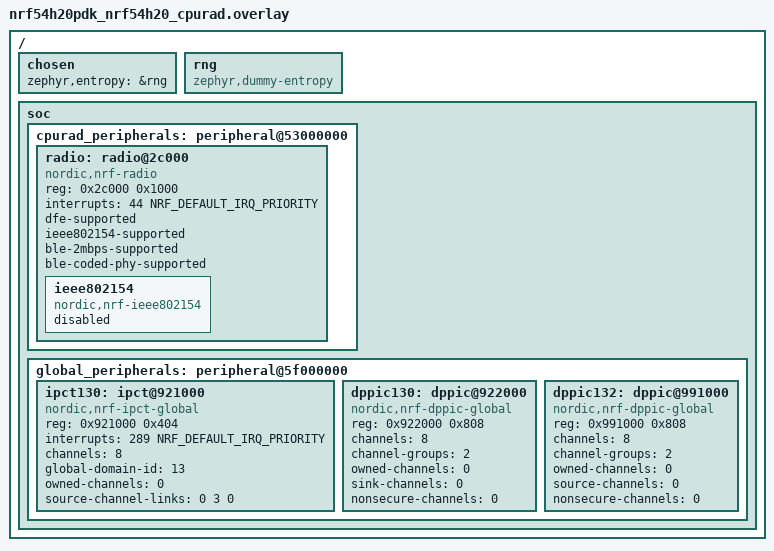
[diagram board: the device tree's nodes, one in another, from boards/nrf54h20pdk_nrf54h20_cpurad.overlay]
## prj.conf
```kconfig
#
# Copyright (c) 2018 Nordic Semiconductor
#
# SPDX-License-Identifier: LicenseRef-Nordic-5-Clause
#
CONFIG_NCS_SAMPLES_DEFAULTS=y

CONFIG_SHELL=y

CONFIG_BT_DEVICE_NAME="Nordic_Throughput"
CONFIG_BT=y
CONFIG_LOG=n
CONFIG_BT_DEBUG_LOG=n
CONFIG_BT_SMP=y
CONFIG_BT_PERIPHERAL=y
CONFIG_BT_CENTRAL=y
CONFIG_BT_MAX_CONN=2
CONFIG_BT_BONDABLE=n

CONFIG_BT_SCAN=y
CONFIG_BT_SCAN_FILTER_ENABLE=y
CONFIG_BT_SCAN_UUID_CNT=1

CONFIG_BT_GATT_CLIENT=y
CONFIG_BT_THROUGHPUT=y

CONFIG_BT_GATT_DM=y
CONFIG_HEAP_MEM_POOL_SIZE=2048

CONFIG_BT_USER_DATA_LEN_UPDATE=y
CONFIG_BT_USER_PHY_UPDATE=y
CONFIG_BT_GAP_AUTO_UPDATE_CONN_PARAMS=n

CONFIG_BT_BUF_ACL_RX_SIZE=502
CONFIG_BT_ATT_PREPARE_COUNT=2
CONFIG_BT_L2CAP_TX_BUF_COUNT=10
CONFIG_BT_L2CAP_TX_MTU=498
CONFIG_BT_L2CAP_DYNAMIC_CHANNEL=y
CONFIG_BT_CONN_TX_MAX=10
CONFIG_BT_BUF_ACL_TX_COUNT=10
CONFIG_BT_BUF_ACL_TX_SIZE=502

CONFIG_BT_CTLR_DATA_LENGTH_MAX=251
CONFIG_BT_CTLR_PHY_2M=y
CONFIG_BT_CTLR_PHY_CODED=y
CONFIG_BT_CTLR_SDC_MAX_CONN_EVENT_LEN_DEFAULT=4000000

CONFIG_DK_LIBRARY=n
CONFIG_DK_LIBRARY_DYNAMIC_BUTTON_HANDLERS=n
```

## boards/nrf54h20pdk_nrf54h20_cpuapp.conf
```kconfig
CONFIG_ENTROPY_DEVICE_RANDOM_GENERATOR=n
CONFIG_HARDWARE_DEVICE_CS_GENERATOR=n
CONFIG_CTR_DRBG_CSPRNG_GENERATOR=n

CONFIG_TEST_RANDOM_GENERATOR=y
CONFIG_TIMER_RANDOM_GENERATOR=y
CONFIG_ENTROPY_DUMMY=y

CONFIG_BT_CTLR=n
CONFIG_BT_HCI_IPC=y
```

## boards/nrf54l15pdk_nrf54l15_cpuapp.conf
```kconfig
# CONFIG_ENTROPY_DEVICE_RANDOM_GENERATOR=n
# CONFIG_HARDWARE_DEVICE_CS_GENERATOR=n
# CONFIG_CTR_DRBG_CSPRNG_GENERATOR=n

# CONFIG_TEST_RANDOM_GENERATOR=y
# CONFIG_TIMER_RANDOM_GENERATOR=y
# CONFIG_ENTROPY_DUMMY=y

CONFIG_BT_CTLR=y
# CONFIG_TMP_RNG=y

# Enable nordic security backend and PSA APIs
CONFIG_NRF_SECURITY=y
CONFIG_MBEDTLS_PSA_CRYPTO_C=y

CONFIG_MBEDTLS_ENABLE_HEAP=y
CONFIG_MBEDTLS_HEAP_SIZE=8192

CONFIG_PSA_WANT_GENERATE_RANDOM=y
```

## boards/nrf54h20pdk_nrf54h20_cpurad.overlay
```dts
/{
    chosen {
        zephyr,entropy = &rng;
    };

    rng: rng {
        compatible = "zephyr,dummy-entropy";
        status = "okay";
    };

    soc {
        cpurad_peripherals: peripheral@53000000 {
            radio: radio@2c000 {
                compatible = "nordic,nrf-radio";
                reg = <0x2c000 0x1000>;
                interrupts = <44 NRF_DEFAULT_IRQ_PRIORITY>;
                status = "okay";
                dfe-supported;
                ieee802154-supported;
                ble-2mbps-supported;
                ble-coded-phy-supported;

                ieee802154: ieee802154 {
                    compatible = "nordic,nrf-ieee802154";
                    status = "disabled";
                };
            };
        };

        global_peripherals: peripheral@5f000000 {
            /* MPSL requires one global DPPI channel which is routed to the radiocore */
            ipct130: ipct@921000 {
                compatible = "nordic,nrf-ipct-global";
                reg = <0x921000 0x404>;
                interrupts = <289 NRF_DEFAULT_IRQ_PRIORITY>;
                channels = <8>;
                global-domain-id = <13>;
                owned-channels = <0>;
                source-channel-links = <0 3 0>;
                status = "okay";
            };

            dppic130: dppic@922000 {
                compatible = "nordic,nrf-dppic-global";
                reg = <0x922000 0x808>;
                channels = <8>;
                channel-groups = <2>;
                owned-channels = <0>;
                sink-channels = <0>;
                nonsecure-channels = <0>;
                status = "okay";
            };

            dppic132: dppic@991000 {
                compatible = "nordic,nrf-dppic-global";
                reg = <0x991000 0x808>;
                channels = <8>;
                channel-groups = <2>;
                owned-channels = <0>;
                source-channels = <0>;
                nonsecure-channels = <0>;
                status = "okay";
            };
        };
    };
};
```

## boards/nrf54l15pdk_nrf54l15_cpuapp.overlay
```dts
/{
    chosen {
        zephyr,entropy = &psa_rng;
        // zephyr,entropy = &rng;
    };

    // rng: rng {
        //     compatible = "zephyr,dummy-entropy";
        //     status = "okay";
    // };

    psa_rng: psa-rng {
        compatible = "zephyr,psa-crypto-rng";
        status = "okay";
    };

};
```

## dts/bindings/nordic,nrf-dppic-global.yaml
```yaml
#
# Copyright (c) 2022 Nordic Semiconductor ASA
#
# SPDX-License-Identifier: LicenseRef-Nordic-4-Clause
#

description: |
  Nordic Global DPPIC
  (Distributed Programmable Peripheral Interconnect Controller)

  Updated DPPIC binding set for Nordic products that have global DPPIC instances
  with inter-bridge functionality. These instances also have split-ownership
  of its channels and channel groups.

compatible: "nordic,nrf-dppic-global"

include:
  - "nordic,nrf-dppic.yaml"
  - "nordic,nrf-dppic-links.yaml"
  - "nordic,nrf-fixed-channel-links.yaml"
  - "nordic,split-channels.yaml"
  - "nordic,split-channel-groups.yaml"

properties:
    channels:
      required: true
      type: int
      description: Number of DPPI channels implemented by the DPPIC.

    channel-groups:
      type: int
      description: |
        Number of DPPI channel groups implemented by the DPPIC.
        If not present, the DPPIC does not implement channel groups.
```

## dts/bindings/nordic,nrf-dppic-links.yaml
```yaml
#
# Copyright (c) 2022 Nordic Semiconductor ASA
#
# SPDX-License-Identifier: LicenseRef-Nordic-4-Clause
#

description: Nordic DPPIC Channel Linking

properties:
    source-channels:
      type: array
      description: |
        Channels that are linked to channels of DPPIC instances on separate
        bridges as publishing sources.

    sink-channels:
      type: array
      description: |
        Channels that are linked to channels of DPPIC instances on separate
        bridges as subscribing sinks.
```

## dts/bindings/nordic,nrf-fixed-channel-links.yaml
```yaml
#
# Copyright (c) 2022 Nordic Semiconductor ASA
#
# SPDX-License-Identifier: LicenseRef-Nordic-4-Clause
#

description: |
  Nordic Fixed Channel Links

  Contains common bindings that describe fixed (hardwired) channel connections
  from a peripheral node to another peripheral node.

properties:
    fixed-channel-links:
      type: phandle-array
      description: |
        A list of ranges of linked channels between this peripheral node and
        another peripheral node. The prop is encoded as
        <&phandle src-ch-start dst-ch-start count>, where:
        - phandle is the phandle of the linked peripheral node
        - src-ch-start is the starting index of the channel range in this node
        - dst-ch-start is the starting index of the channel range in the linked
          node
        - count is the number of consecutive linked channels starting at the
          start indices

fixed-channel-link-cells:
  - src-ch-start
  - dst-ch-start
  - count
```

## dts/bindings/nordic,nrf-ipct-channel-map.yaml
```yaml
#
# Copyright (c) 2022 Nordic Semiconductor ASA
#
# SPDX-License-Identifier: LicenseRef-Nordic-4-Clause
#

description: Nordic IPCT Channel Map

properties:
    source-channel-links:
      type: array
      description: |
        Mapping of IPCT channels that are mapped between two IPCT instances on
        separate domains, in which a channel on this IPCT node is considered
        the source. This array is then comprised of a 3-integer-wide "unit"
        that defines one connection of the mapping. The format of this unit
        is <source_channel sink_domain_id sink_channel>. Units are sequential
        in the array, therefore requiring the length of this property to be
        a factor of 3.

        For example, if channel 2 is to be mapped to Secure Domain (ID: 1) IPCT
        channel 4, then the array "unit" would be <2 1 4>.

    sink-channel-links:
      type: array
      description: |
        Mapping of IPCT channels that are mapped between two IPCT instances on
        separate domains, in which a channel on this IPCT node is considered
        the sink. This array is then comprised of a 3-integer-wide "unit"
        that defines one connection of the mapping. The format of this unit
        is <sink_channel source_domain_id source_channel>. Units are sequential
        in the array, therefore requiring the length of this property to be
        a factor of 3.

        For example, if channel 2 is to be mapped to Secure Domain (ID: 1) IPCT
        channel 4, then the array "unit" would be <2 1 4>.
```

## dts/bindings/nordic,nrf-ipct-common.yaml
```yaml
#
# Copyright (c) 2022 Nordic Semiconductor ASA
#
# SPDX-License-Identifier: LicenseRef-Nordic-4-Clause
#

description: Nordic IPCT (Interprocessor Communication Transceiver)

include: ["base.yaml", "nordic,nrf-ipct-channel-map.yaml"]

properties:
    reg:
      required: true

    channels:
      type: int
      required: true
      description: Number of channels implemented by the IPCT instance.
```

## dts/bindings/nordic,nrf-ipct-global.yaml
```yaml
#
# Copyright (c) 2022 Nordic Semiconductor ASA
#
# SPDX-License-Identifier: LicenseRef-Nordic-4-Clause
#

description: Nordic Global IPCT (Interprocessor Communication Transceiver)

compatible: "nordic,nrf-ipct-global"

include: ["nordic,nrf-ipct-common.yaml", "nordic,split-channels.yaml"]

properties:
    global-domain-id:
      required: true
      type: int
      description: |
        Global IPCT instances reside on specific buses within the Global Domain,
        such as fast and slow, which have different IDs that do not match the
        standard Global Domain ID presented in their address.
```

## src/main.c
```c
/*
 * Copyright (c) 2018 Nordic Semiconductor ASA
 *
 * SPDX-License-Identifier: LicenseRef-Nordic-5-Clause
 */

#include <zephyr/kernel.h>
#include <zephyr/console/console.h>
#include <zephyr/sys/printk.h>
#include <string.h>
#include <stdlib.h>
#include <zephyr/types.h>

#include <zephyr/bluetooth/bluetooth.h>
#include <zephyr/bluetooth/crypto.h>
#include <zephyr/bluetooth/conn.h>
#include <zephyr/bluetooth/gatt.h>
#include <zephyr/bluetooth/hci.h>
#include <zephyr/bluetooth/uuid.h>
#include <bluetooth/services/throughput.h>
#include <bluetooth/scan.h>
#include <bluetooth/gatt_dm.h>

#include <zephyr/shell/shell_uart.h>

// #include <dk_buttons_and_leds.h>

#ifdef shell_error
#undef shell_error
#endif

#define shell_error(sh, ...) printk(__VA_ARGS__)

#include "main.h"

#define DEVICE_NAME	CONFIG_BT_DEVICE_NAME
#define DEVICE_NAME_LEN (sizeof(DEVICE_NAME) - 1)
#define INTERVAL_MIN	0x6	/* 6 units, 7.5 ms, only used to setup connection */
#define INTERVAL_MAX	0x6	/* 6 units, 7.5 ms, only used to setup connection */

#define THROUGHPUT_CONFIG_TIMEOUT K_SECONDS(20)

static K_SEM_DEFINE(throughput_sem, 0, 1);

static volatile bool data_length_req;
static volatile bool test_ready;
static struct bt_conn *default_conn;
static struct bt_throughput throughput;
static struct bt_uuid *uuid128 = BT_UUID_THROUGHPUT;
static struct bt_gatt_exchange_params exchange_params;
static struct bt_le_conn_param *conn_param =
	BT_LE_CONN_PARAM(INTERVAL_MIN, INTERVAL_MAX, 0, 400);

static const struct bt_data ad[] = {
	BT_DATA_BYTES(BT_DATA_FLAGS, (BT_LE_AD_GENERAL | BT_LE_AD_NO_BREDR)),
	BT_DATA_BYTES(BT_DATA_UUID128_ALL,
		0xBB, 0x4A, 0xFF, 0x4F, 0xAD, 0x03, 0x41, 0x5D,
		0xA9, 0x6C, 0x9D, 0x6C, 0xDD, 0xDA, 0x83, 0x04),
};

static const struct bt_data sd[] = {
	BT_DATA(BT_DATA_NAME_COMPLETE, DEVICE_NAME, DEVICE_NAME_LEN),
};

static const char img[] =
#include "img.file"
;

// static void button_handler_cb(uint32_t button_state, uint32_t has_changed);

static const char *phy2str(uint8_t phy)
{
	switch (phy) {
	case 0: return "No packets";
	case BT_GAP_LE_PHY_1M: return "LE 1M";
	case BT_GAP_LE_PHY_2M: return "LE 2M";
	case BT_GAP_LE_PHY_CODED: return "LE Coded";
	default: return "Unknown";
	}
}

static void instruction_print(void)
{
	printk("\nType 'config' to change the configuration parameters.\n");
	printk("You can use the Tab key to autocomplete your input.\n");
	printk("Type 'run' when you are ready to run the test.\n");
}

void scan_filter_match(struct bt_scan_device_info *device_info,
		       struct bt_scan_filter_match *filter_match,
		       bool connectable)
{
	char addr[BT_ADDR_LE_STR_LEN];

	bt_addr_le_to_str(device_info->recv_info->addr, addr, sizeof(addr));

	printk("Filters matched. Address: %s connectable: %d\n",
		addr, connectable);
}

void scan_filter_no_match(struct bt_scan_device_info *device_info,
			  bool connectable)
{
	char addr[BT_ADDR_LE_STR_LEN];

	bt_addr_le_to_str(device_info->recv_info->addr, addr, sizeof(addr));

	printk("Filter not match. Address: %s connectable: %d\n",
				addr, connectable);
}

void scan_connecting_error(struct bt_scan_device_info *device_info)
{
	printk("Connecting failed\n");
}

BT_SCAN_CB_INIT(scan_cb, scan_filter_match, scan_filter_no_match,
		scan_connecting_error, NULL);

static void exchange_func(struct bt_conn *conn, uint8_t att_err,
			  struct bt_gatt_exchange_params *params)
{
	struct bt_conn_info info = {0};
	int err;

	printk("MTU exchange %s\n", att_err == 0 ? "successful" : "failed");

	err = bt_conn_get_info(conn, &info);
	if (err) {
		printk("Failed to get connection info %d\n", err);
		return;
	}

	if (info.role == BT_CONN_ROLE_CENTRAL) {
		instruction_print();
		test_ready = true;
	}
}

static void discovery_complete(struct bt_gatt_dm *dm,
			       void *context)
{
	int err;
	struct bt_throughput *throughput = context;

	printk("Service discovery completed\n");

	bt_gatt_dm_data_print(dm);
	bt_throughput_handles_assign(dm, throughput);
	bt_gatt_dm_data_release(dm);

	exchange_params.func = exchange_func;

	err = bt_gatt_exchange_mtu(default_conn, &exchange_params);
	if (err) {
		printk("MTU exchange failed (err %d)\n", err);
	} else {
		printk("MTU exchange pending\n");
	}
}

static void discovery_service_not_found(struct bt_conn *conn,
					void *context)
{
	printk("Service not found\n");
}

static void discovery_error(struct bt_conn *conn,
			    int err,
			    void *context)
{
	printk("Error while discovering GATT database: (%d)\n", err);
}

struct bt_gatt_dm_cb discovery_cb = {
	.completed         = discovery_complete,
	.service_not_found = discovery_service_not_found,
	.error_found       = discovery_error,
};

static void connected(struct bt_conn *conn, uint8_t hci_err)
{
	struct bt_conn_info info = {0};
	int err;

	if (hci_err) {
		if (hci_err == BT_HCI_ERR_UNKNOWN_CONN_ID) {
			/* Canceled creating connection */
			return;
		}

		printk("Connection failed (err 0x%02x)\n", hci_err);
		return;
	}

	if (default_conn) {
		printk("Connection exists, disconnect second connection\n");
		bt_conn_disconnect(conn, BT_HCI_ERR_REMOTE_USER_TERM_CONN);
		return;
	}

	default_conn = bt_conn_ref(conn);

	err = bt_conn_get_info(default_conn, &info);
	if (err) {
		printk("Failed to get connection info %d\n", err);
		return;
	}

	printk("Connected as %s\n",
	       info.role == BT_CONN_ROLE_CENTRAL ? "central" : "peripheral");
	printk("Conn. interval is %u units\n", info.le.interval);

	// if (info.role == BT_CONN_ROLE_PERIPHERAL) {
	// 	err = bt_conn_set_security(conn, BT_SECURITY_L2);
	// 	if (err) {
	// 		printk("Failed to set security: %d\n", err);
	// 	}
	// }

	if (info.role == BT_CONN_ROLE_CENTRAL) {
		err = bt_gatt_dm_start(default_conn,
				       BT_UUID_THROUGHPUT,
				       &discovery_cb,
				       &throughput);
		if (err) {
			printk("Discover failed (err %d)\n", err);
		}
	}
}

void security_changed(struct bt_conn *conn, bt_security_t level,
				 enum bt_security_err security_err)
{
	printk("Security changed: level %i, err: %i\n", level, security_err);

	if (security_err != 0) {
		printk("Failed to encrypt link\n");
		bt_conn_disconnect(conn, BT_HCI_ERR_PAIRING_NOT_SUPPORTED);
		return;
	}

	struct bt_conn_info info = {0};
	int err;

	err = bt_conn_get_info(default_conn, &info);
	if (info.role == BT_CONN_ROLE_CENTRAL) {
		err = bt_gatt_dm_start(default_conn,
				       BT_UUID_THROUGHPUT,
				       &discovery_cb,
				       &throughput);
		if (err) {
			printk("Discover failed (err %d)\n", err);
		}
	}
}

static void scan_init(void)
{
	int err;
	struct bt_le_scan_param scan_param = {
		.type = BT_LE_SCAN_TYPE_PASSIVE,
		.options = BT_LE_SCAN_OPT_FILTER_DUPLICATE,
		.interval = 0x0010,
		.window = 0x0010,
	};

	struct bt_scan_init_param scan_init = {
		.connect_if_match = 1,
		.scan_param = &scan_param,
		.conn_param = conn_param
	};

	bt_scan_init(&scan_init);
	bt_scan_cb_register(&scan_cb);

	err = bt_scan_filter_add(BT_SCAN_FILTER_TYPE_UUID, uuid128);
	if (err) {
		printk("Scanning filters cannot be set\n");

		return;
	}

	err = bt_scan_filter_enable(BT_SCAN_UUID_FILTER, false);
	if (err) {
		printk("Filters cannot be turned on\n");
	}
}

static void scan_start(void)
{
	int err;

	err = bt_scan_start(BT_SCAN_TYPE_SCAN_PASSIVE);
	if (err) {
		printk("Starting scanning failed (err %d)\n", err);
		return;
	}
}

static void adv_start(void)
{
	struct bt_le_adv_param *adv_param =
		BT_LE_ADV_PARAM(BT_LE_ADV_OPT_CONNECTABLE |
				BT_LE_ADV_OPT_ONE_TIME,
				BT_GAP_ADV_FAST_INT_MIN_2,
				BT_GAP_ADV_FAST_INT_MAX_2,
				NULL);
	int err;

	err = bt_le_adv_start(adv_param, ad, ARRAY_SIZE(ad), sd,
			      ARRAY_SIZE(sd));
	if (err) {
		printk("Failed to start advertiser (%d)\n", err);
		return;
	}
}

static void disconnected(struct bt_conn *conn, uint8_t reason)
{
	struct bt_conn_info info = {0};
	int err;

	printk("Disconnected (reason 0x%02x)\n", reason);

	test_ready = false;
	if (default_conn) {
		bt_conn_unref(default_conn);
		default_conn = NULL;
	}

	err = bt_conn_get_info(conn, &info);
	if (err) {
		printk("Failed to get connection info (%d)\n", err);
		return;
	}

	/* Re-connect using same roles */
	if (info.role == BT_CONN_ROLE_CENTRAL) {
		scan_start();
	} else {
		adv_start();
	}
}

static bool le_param_req(struct bt_conn *conn, struct bt_le_conn_param *param)
{
	printk("Connection parameters update request received.\n");
	printk("Minimum interval: %d, Maximum interval: %d\n",
	       param->interval_min, param->interval_max);
	printk("Latency: %d, Timeout: %d\n", param->latency, param->timeout);

	return true;
}

static void le_param_updated(struct bt_conn *conn, uint16_t interval,
			     uint16_t latency, uint16_t timeout)
{
	printk("Connection parameters updated.\n"
	       " interval: %d, latency: %d, timeout: %d\n",
	       interval, latency, timeout);

	k_sem_give(&throughput_sem);
}

static void le_phy_updated(struct bt_conn *conn,
			   struct bt_conn_le_phy_info *param)
{
	printk("LE PHY updated: TX PHY %s, RX PHY %s\n",
	       phy2str(param->tx_phy), phy2str(param->rx_phy));

	k_sem_give(&throughput_sem);
}

static void le_data_length_updated(struct bt_conn *conn,
				   struct bt_conn_le_data_len_info *info)
{
	if (!data_length_req) {
		return;
	}

	printk("LE data len updated: TX (len: %d time: %d)"
	       " RX (len: %d time: %d)\n", info->tx_max_len,
	       info->tx_max_time, info->rx_max_len, info->rx_max_time);

	data_length_req = false;
	k_sem_give(&throughput_sem);
}

static uint8_t throughput_read(const struct bt_throughput_metrics *met)
{
	printk("[peer] received %u bytes (%u KB)"
	       " in %u GATT writes at %u bps\n",
	       met->write_len, met->write_len / 1024, met->write_count,
	       met->write_rate);

	k_sem_give(&throughput_sem);

	return BT_GATT_ITER_STOP;
}

static void throughput_received(const struct bt_throughput_metrics *met)
{
	static uint32_t kb;

	if (met->write_len == 0) {
		kb = 0;
		printk("\n");

		return;
	}

	if ((met->write_len / 1024) != kb) {
		kb = (met->write_len / 1024);
		printk("=");
	}
}

static void throughput_send(const struct bt_throughput_metrics *met)
{
	printk("\n[local] received %u bytes (%u KB)"
		" in %u GATT writes at %u bps\n",
		met->write_len, met->write_len / 1024,
		met->write_count, met->write_rate);
}

static const struct bt_throughput_cb throughput_cb = {
	.data_read = throughput_read,
	.data_received = throughput_received,
	.data_send = throughput_send
};

// static struct button_handler button = {
// 	.cb = button_handler_cb,
// };

void select_role(bool is_central)
{
	int err;
	static bool role_selected;

	if (role_selected) {
		printk("\nCannot change role after it was selected once.\n");
		return;
	} else if (is_central) {
		printk("\nCentral. Starting scanning\n");
		scan_start();
	} else {
		printk("\nPeripheral. Starting advertising\n");
		adv_start();
	}

	role_selected = true;

	/* The role has been selected, button are not needed any more. */
	// err = dk_button_handler_remove(&button);
	// if (err) {
	// 	printk("Button disable error: %d\n", err);
	// }
}

// static void button_handler_cb(uint32_t button_state, uint32_t has_changed)
// {
// 	ARG_UNUSED(has_changed);

// 	if (button_state & DK_BTN1_MSK) {
// 		select_role(true);
// 	} else if (button_state & DK_BTN2_MSK) {
// 		select_role(false);
// 	}
// }

static void buttons_init(void)
{
	int err;

	// err = dk_buttons_init(NULL);
	// if (err) {
	// 	printk("Buttons initialization failed.\n");
	// 	return;
	// }

	// /* Add dynamic buttons handler. Buttons should be activated only when
	//  * during the board role choosing.
	//  */
	// dk_button_handler_add(&button);
}

static int connection_configuration_set(const struct shell *shell,
			const struct bt_le_conn_param *conn_param,
			const struct bt_conn_le_phy_param *phy,
			const struct bt_conn_le_data_len_param *data_len)
{
	int err;
	struct bt_conn_info info = {0};

	err = bt_conn_get_info(default_conn, &info);
	if (err) {
		shell_error(shell, "Failed to get connection info %d", err);
		return err;
	}

	if (info.role != BT_CONN_ROLE_CENTRAL) {
		shell_error(shell,
		"'run' command shall be executed only on the central board");
	}

	err = bt_conn_le_phy_update(default_conn, phy);
	if (err) {
		shell_error(shell, "PHY update failed: %d\n", err);
		return err;
	}

	printk("PHY update pending\n");
	err = k_sem_take(&throughput_sem, THROUGHPUT_CONFIG_TIMEOUT);
	if (err) {
		shell_error(shell, "PHY update timeout");
		return err;
	}

	if (info.le.interval != conn_param->interval_max) {
		err = bt_conn_le_param_update(default_conn, conn_param);
		if (err) {
			shell_error(shell,
				    "Connection parameters update failed: %d",
				    err);
			return err;
		}

		printk("Connection parameters update pending\n");
		err = k_sem_take(&throughput_sem, THROUGHPUT_CONFIG_TIMEOUT);
		if (err) {
			shell_error(shell,
				    "Connection parameters update timeout");
			return err;
		}
	}

	if (info.le.data_len->tx_max_len != data_len->tx_max_len) {
		data_length_req = true;

		err = bt_conn_le_data_len_update(default_conn, data_len);
		if (err) {
			shell_error(shell, "LE data length update failed: %d",
				    err);
			return err;
		}

		printk("LE Data length update pending\n");
		err = k_sem_take(&throughput_sem, THROUGHPUT_CONFIG_TIMEOUT);
		if (err) {
			shell_error(shell, "LE Data Length update timeout");
			return err;
		}
	}

	return 0;
}

int test_run(const struct shell *shell,
	     const struct bt_le_conn_param *conn_param,
	     const struct bt_conn_le_phy_param *phy,
	     const struct bt_conn_le_data_len_param *data_len)
{
	int err;
	uint64_t stamp;
	int64_t delta;
	uint32_t data = 0;

	const char *img_ptr = img;
	char str_buf[7];
	int str_len;


	/* a dummy data buffer */
	static char dummy[495];

	if (!default_conn) {
		shell_error(shell, "Device is disconnected %s",
			    "Connect to the peer device before running test");
		return -EFAULT;
	}

	if (!test_ready) {
		shell_error(shell, "Device is not ready."
			"Please wait for the service discovery and MTU exchange end");
		return 0;
	}

	// printk("\n==== Starting throughput test ====\n");
	printk("\n==== Starting throughput test ====");

	err = connection_configuration_set(shell, conn_param, phy, data_len);
	if (err) {
		return err;
	}

	/* Make sure that all BLE procedures are finished. */
	k_sleep(K_MSEC(500));

	/* reset peer metrics */
	err = bt_throughput_write(&throughput, dummy, 1);
	if (err) {
		shell_error(shell, "Reset peer metrics failed.");
		return err;
	}

	/* get cycle stamp */
	stamp = k_uptime_get_32();

	if (IS_ENABLED(CONFIG_BT_THROUGHPUT_FILE)) {
		while (*img_ptr) {
			err = bt_throughput_write(&throughput, dummy, 495);
			if (err) {
				shell_error(shell, "GATT write failed (err %d)", err);
				break;
			}

			/* print graphics */
			str_len = (*img_ptr == '\x1b') ? 6 : 1;
			memcpy(str_buf, img_ptr, str_len);
			str_buf[str_len] = '\0';
			img_ptr += str_len;
			printk("%s", str_buf);

			data += 495;
		}
	} else {
		delta = 0;
		while (true) {
			err = bt_throughput_write(&throughput, dummy, 495);
			if (err) {
				shell_error(shell, "GATT write failed (err %d)", err);
				break;
			}
			data += 495;
			if (k_uptime_get_32() - stamp > CONFIG_BT_THROUGHPUT_DURATION) {
				break;
			}
		}
	}

	delta = k_uptime_delta(&stamp);

	printk("\nDone\n");
	printk("[local] sent %u bytes (%u KB) in %lld ms at %llu kbps\n",
	       data, data / 1024, delta, ((uint64_t)data * 8 / delta));

	/* read back char from peer */
	err = bt_throughput_read(&throughput);
	if (err) {
		shell_error(shell, "GATT read failed (err %d)", err);
		return err;
	}

	k_sem_take(&throughput_sem, THROUGHPUT_CONFIG_TIMEOUT);

	instruction_print();

	return 0;
}

BT_CONN_CB_DEFINE(conn_callbacks) = {
	.connected = connected,
	.disconnected = disconnected,
	.le_param_req = le_param_req,
	.le_param_updated = le_param_updated,
	.le_phy_updated = le_phy_updated,
	.le_data_len_updated = le_data_length_updated,
	.security_changed = security_changed
};

int main(void)
{
	int err;

	printk("Starting Bluetooth Throughput example\n");

	err = bt_enable(NULL);
	if (err) {
		printk("Bluetooth init failed (err %d)\n", err);
		return 0;
	}

	printk("Bluetooth initialized\n");

	scan_init();

	err = bt_throughput_init(&throughput, &throughput_cb);
	if (err) {
		printk("Throughput service initialization failed.\n");
		return 0;
	}

	printk("\n");
	printk("Press button 1 or type \"central\" on the central board.\n");
	printk("Press button 2 or type \"peripheral\" on the peripheral board.\n");

	buttons_init();

#if defined(CONFIG_SOC_SERIES_NRF54LX)
	select_role(false); /* Force peripheral */
#elif defined(CONFIG_SOC_SERIES_NRF54HX)
	select_role(true); /* Force central */
#endif

extern struct test_params {
	struct bt_le_conn_param *conn_param;
	struct bt_conn_le_phy_param *phy;
	struct bt_conn_le_data_len_param *data_len;
} *p_test_params;

	while (!test_ready) {
		k_sleep(K_SECONDS(5));
	}


		test_run(shell_backend_get_by_name("shell_uart"), p_test_params->conn_param, p_test_params->phy,
			p_test_params->data_len);

	return 0;
}
```

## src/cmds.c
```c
/*
 * Copyright (c) 2020 Nordic Semiconductor ASA
 *
 * SPDX-License-Identifier: LicenseRef-Nordic-5-Clause
 */

#include <stdlib.h>

#include <zephyr/bluetooth/conn.h>

#include <errno.h>
#include <zephyr/shell/shell.h>
#include <zephyr/types.h>

#include "main.h"

#define INTERVAL_MIN 0x140 /* 320 units, 400 ms */
#define INTERVAL_MAX 0x140 /* 320 units, 400 ms */
#define CONN_LATENCY 0

#define MIN_CONN_INTERVAL   6
#define MAX_CONN_INTERVAL   3200
#define SUPERVISION_TIMEOUT 1000

static struct test_params {
	struct bt_le_conn_param *conn_param;
	struct bt_conn_le_phy_param *phy;
	struct bt_conn_le_data_len_param *data_len;
} test_params = {
	.conn_param = BT_LE_CONN_PARAM(INTERVAL_MIN, INTERVAL_MAX, CONN_LATENCY,
				       SUPERVISION_TIMEOUT),
	.phy = BT_CONN_LE_PHY_PARAM_2M,
	.data_len = BT_LE_DATA_LEN_PARAM_MAX
};

struct test_params *p_test_params = &test_params;

static const char *phy_str(const struct bt_conn_le_phy_param *phy)
{
	static const char *const str[] = {
		"1 Mbps",
		"2 Mbps",
		"Coded S2",
		"Coded S8",
		"Unknown"
	};

	switch (phy->pref_tx_phy) {
	case BT_GAP_LE_PHY_1M:
		return str[0];

	case BT_GAP_LE_PHY_2M:
		return str[1];

	case BT_GAP_LE_PHY_CODED:
		if (phy->options == BT_CONN_LE_PHY_OPT_CODED_S2) {
			return str[2];
		} else if (phy->options == BT_CONN_LE_PHY_OPT_CODED_S8) {
			return str[3];
		}

	default:
		return str[4];
	}
}

static int default_cmd(const struct shell *shell, size_t argc,
		       char **argv)
{
	if (argc == 1) {
		shell_help(shell);
		return SHELL_CMD_HELP_PRINTED;
	}

	if (argc > 2) {
		shell_error(shell, "%s: bad parameters count.", argv[0]);
		return -EINVAL;
	}

	if (argc == 2) {
		shell_error(shell, "Uknown argument: %s", argv[1]);
		return -EINVAL;
	}

	return 0;
}

static int cmd_phy_1m(const struct shell *shell, size_t argc,
		      char **argv)
{
	test_params.phy->options = BT_CONN_LE_PHY_OPT_NONE;
	test_params.phy->pref_rx_phy = BT_GAP_LE_PHY_1M;
	test_params.phy->pref_tx_phy = BT_GAP_LE_PHY_1M;

	shell_print(shell, "PHY set to: %s", phy_str(test_params.phy));

	return 0;
}

static int cmd_phy_2m(const struct shell *shell, size_t argc,
		      char **argv)
{
	test_params.phy->options = BT_CONN_LE_PHY_OPT_NONE;
	test_params.phy->pref_rx_phy = BT_GAP_LE_PHY_2M;
	test_params.phy->pref_tx_phy = BT_GAP_LE_PHY_2M;

	shell_print(shell, "PHY set to: %s", phy_str(test_params.phy));

	return 0;
}

#if defined(RADIO_MODE_MODE_Ble_LR500Kbit) || defined(NRF5340_XXAA_APPLICATION)
static int cmd_phy_coded_s2(const struct shell *shell, size_t argc,
			    char **argv)
{
	test_params.phy->options = BT_CONN_LE_PHY_OPT_CODED_S2;
	test_params.phy->pref_rx_phy = BT_GAP_LE_PHY_CODED;
	test_params.phy->pref_tx_phy = BT_GAP_LE_PHY_CODED;

	shell_print(shell, "PHY set to: %s", phy_str(test_params.phy));

	return 0;
}
#endif /* defined(RADIO_MODE_MODE_Ble_LR1500Kbit) ||
	* defined(NRF5340_XXAA_APPLICATION)
	*/

#if defined(RADIO_MODE_MODE_Ble_LR125Kbit) || defined(NRF5340_XXAA_APPLICATION)
static int cmd_phy_coded_s8(const struct shell *shell, size_t argc,
			    char **argv)
{
	test_params.phy->options = BT_CONN_LE_PHY_OPT_CODED_S8;
	test_params.phy->pref_rx_phy = BT_GAP_LE_PHY_CODED;
	test_params.phy->pref_tx_phy = BT_GAP_LE_PHY_CODED;

	shell_print(shell, "PHY set to: %s",
		    phy_str(test_params.phy));

	return 0;
}
#endif /* defined(RADIO_MODE_MODE_Ble_LR125Kbit) ||
	* defined(NRF5340_XXAA_APPLICATION)
	*/

static int data_len_cmd(const struct shell *shell, size_t argc,
			char **argv)
{
	uint16_t data_len;

	if (argc == 1) {
		shell_help(shell);
		return SHELL_CMD_HELP_PRINTED;
	}

	if (argc > 2) {
		shell_error(shell, "%s: bad parameters count", argv[0]);
		return -EINVAL;
	}

	data_len = strtol(argv[1], NULL, 10);

	if ((data_len < BT_GAP_DATA_LEN_DEFAULT) ||
	    (data_len > BT_GAP_DATA_LEN_MAX)) {
		shell_error(shell, "%s: Invalid setting: %d", argv[0],
			    data_len);
		shell_error(shell,
			    "LE Data Packet Length must be between: %d and %d",
			    BT_GAP_DATA_LEN_DEFAULT, BT_GAP_DATA_LEN_MAX);
		return -EINVAL;
	}

	test_params.data_len->tx_max_len = data_len;
	test_params.data_len->tx_max_time = BT_GAP_DATA_TIME_MAX;

	shell_print(shell, "LE Data Packet Length set to: %d", data_len);

	return 0;
}

static int conn_interval_cmd(const struct shell *shell, size_t argc,
			     char **argv)
{
	uint16_t interval;

	if (argc == 1) {
		shell_help(shell);
		return SHELL_CMD_HELP_PRINTED;
	}

	if (argc > 2) {
		shell_error(shell, "%s: bad parameters count", argv[0]);
		return -EINVAL;
	}

	interval = strtol(argv[1], NULL, 10);

	if ((interval < MIN_CONN_INTERVAL) ||
	    (interval > MAX_CONN_INTERVAL)) {
		shell_error(shell, "%s: Invalid setting: %d", argv[0],
			    interval);
		shell_error(shell,
			    "Connection interval must be between: %d and %d",
			    MIN_CONN_INTERVAL, MAX_CONN_INTERVAL);
		return -EINVAL;
	}

	test_params.conn_param->interval_max = interval;
	test_params.conn_param->interval_min = interval;
	test_params.conn_param->latency = 0;
	test_params.conn_param->timeout = SUPERVISION_TIMEOUT;

	shell_print(shell, "Connection interval set to: %d",
		    interval);

	return 0;
}

static int print_cmd(const struct shell *shell, size_t argc,
		     char **argv)
{
	shell_print(shell, "==== Current test configuration ====\n");
	shell_print(shell, "Data length:\t\t%d\n"
		    "Connection interval:\t%d units\n"
		    "Preferred PHY:\t\t%s\n",
		    test_params.data_len->tx_max_len,
		    test_params.conn_param->interval_min,
		    phy_str(test_params.phy));
	return 0;
}

SHELL_STATIC_SUBCMD_SET_CREATE(phy_sub,
	SHELL_CMD(1M, NULL, "Set preferred PHY to 1Mbps", cmd_phy_1m),
	SHELL_CMD(2M, NULL, "Set preferred PHY to 2Mbps", cmd_phy_2m),
#if defined(RADIO_MODE_MODE_Ble_LR500Kbit) || defined(NRF5340_XXAA_APPLICATION)
	SHELL_CMD(coded_s2, NULL, "Set preferred PHY to Coded S2",
		  cmd_phy_coded_s2),
#endif
#if defined(RADIO_MODE_MODE_Ble_LR125Kbit) || defined(NRF5340_XXAA_APPLICATION)
	SHELL_CMD(coded_s8, NULL, "Set preferred PHY to Coded S8",
		  cmd_phy_coded_s8),
#endif
	SHELL_SUBCMD_SET_END
);

SHELL_STATIC_SUBCMD_SET_CREATE(sub_config,
	SHELL_CMD(data_length, NULL, "Configure data length", data_len_cmd),
	SHELL_CMD(conn_interval, NULL,
		  "Configure connection interval <1.25ms units>",
		  conn_interval_cmd),
	SHELL_CMD(phy, &phy_sub, "Configure connection interval", default_cmd),
	SHELL_CMD(print, NULL, "Print current configuration", print_cmd),
	SHELL_SUBCMD_SET_END
);


static int test_run_cmd(const struct shell *shell, size_t argc,
			char **argv)
{
	return test_run(shell, test_params.conn_param, test_params.phy,
			test_params.data_len);
}

static int test_central_cmd(const struct shell *shell, size_t argc,
			    char **argv)
{
	select_role(true);
	return 0;
}

static int test_peripheral_cmd(const struct shell *shell, size_t argc,
			       char **argv)
{
	select_role(false);
	return 0;
}

SHELL_CMD_REGISTER(config, &sub_config, "Configure the example", default_cmd);
SHELL_CMD_REGISTER(run, NULL, "Run the test", test_run_cmd);
SHELL_CMD_REGISTER(central, NULL, "Select central role", test_central_cmd);
SHELL_CMD_REGISTER(peripheral, NULL, "Select peripheral role", test_peripheral_cmd);
```
